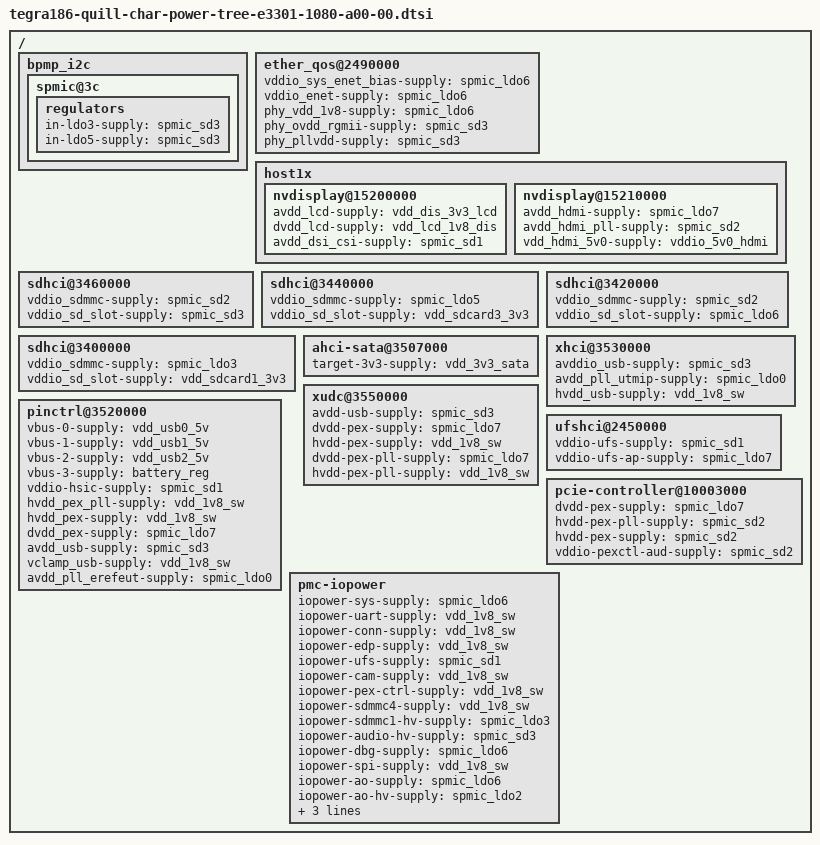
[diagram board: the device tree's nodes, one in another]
/*
 * Copyright (c) 2015, NVIDIA CORPORATION.  All rights reserved.
 *
 * This program is free software; you can redistribute it and/or modify
 * it under the terms of the GNU General Public License as published by
 * the Free Software Foundation; either version 2 of the License, or
 * (at your option) any later version.
 *
 * This program is distributed in the hope that it will be useful, but WITHOUT
 * ANY WARRANTY; without even the implied warranty of MERCHANTABILITY or
 * FITNESS FOR A PARTICULAR PURPOSE.  See the GNU General Public License for
 * more details.
 *
 */

#include "tegra186-quill-pb-spmic-e3301-1000-a00-00.dtsi"
#include "tegra186-quill-pb-fixed-e3301-1000-a00-00.dtsi"
#include "tegra186-cvb-slt-p2598-a00-e3340-1099-a00-00.dtsi"

/ {
	bpmp_i2c {
		spmic@3c {
			regulators {
				in-ldo3-supply = <&spmic_sd3>;
				in-ldo5-supply = <&spmic_sd3>;
			};
		};
	};

	ether_qos@2490000 {
		vddio_sys_enet_bias-supply = <&spmic_ldo6>;
		vddio_enet-supply = <&spmic_ldo6>;
		phy_vdd_1v8-supply = <&spmic_ldo6>;
		phy_ovdd_rgmii-supply = <&spmic_sd3>;
		phy_pllvdd-supply = <&spmic_sd3>;
	};

	host1x {
		nvdisplay@15200000 {
			avdd_lcd-supply = <&vdd_dis_3v3_lcd>;
			dvdd_lcd-supply = <&vdd_lcd_1v8_dis>;
			avdd_dsi_csi-supply = <&spmic_sd1>;
		};
		nvdisplay@15210000 {
			avdd_hdmi-supply = <&spmic_ldo7>;
			avdd_hdmi_pll-supply = <&spmic_sd2>;
			vdd_hdmi_5v0-supply = <&vddio_5v0_hdmi>;
		};
	};

	sdhci@3460000 {
		vddio_sdmmc-supply = <&spmic_sd2>;
		vddio_sd_slot-supply = <&spmic_sd3>;
	};

	sdhci@3440000 {
		vddio_sdmmc-supply = <&spmic_ldo5>;
		vddio_sd_slot-supply = <&vdd_sdcard3_3v3>;
	};

	sdhci@3420000 {
		vddio_sdmmc-supply = <&spmic_sd2>;
		vddio_sd_slot-supply = <&spmic_ldo6>;
	};

	sdhci@3400000 {
		vddio_sdmmc-supply = <&spmic_ldo3>;
		vddio_sd_slot-supply = <&vdd_sdcard1_3v3>;
	};

	ahci-sata@3507000 {
		target-3v3-supply = <&vdd_3v3_sata>;
	};

	xhci@3530000 {
		avddio_usb-supply = <&spmic_sd3>;
		avdd_pll_utmip-supply = <&spmic_ldo0>;
		hvdd_usb-supply =  <&vdd_1v8_sw>;
	};

	xudc@3550000 {
		avdd-usb-supply = <&spmic_sd3>;
		dvdd-pex-supply = <&spmic_ldo7>;
		hvdd-pex-supply =  <&vdd_1v8_sw>;
		dvdd-pex-pll-supply = <&spmic_ldo7>;
		hvdd-pex-pll-supply = <&vdd_1v8_sw>;
	};

	pinctrl@3520000 {
		vbus-0-supply = <&vdd_usb0_5v>;
		vbus-1-supply = <&vdd_usb1_5v>;
		vbus-2-supply = <&vdd_usb2_5v>;
		vbus-3-supply = <&battery_reg>;
		vddio-hsic-supply = <&spmic_sd1>;
		hvdd_pex_pll-supply = <&vdd_1v8_sw>;
		hvdd_pex-supply = <&vdd_1v8_sw>;
		dvdd_pex-supply = <&spmic_ldo7>;
		avdd_usb-supply = <&spmic_sd3>;
		vclamp_usb-supply = <&vdd_1v8_sw>;
		avdd_pll_erefeut-supply = <&spmic_ldo0>;
	};

	ufshci@2450000 {
		vddio-ufs-supply = <&spmic_sd1>;
		vddio-ufs-ap-supply = <&spmic_ldo7>;
	};

	pcie-controller@10003000 {
		dvdd-pex-supply = <&spmic_ldo7>;
		hvdd-pex-pll-supply = <&spmic_sd2>;
		hvdd-pex-supply = <&spmic_sd2>;
		vddio-pexctl-aud-supply = <&spmic_sd2>;
	};

	pmc-iopower {
		iopower-sys-supply = <&spmic_ldo6>;
		iopower-uart-supply = <&vdd_1v8_sw>;
		iopower-conn-supply = <&vdd_1v8_sw>;
		iopower-edp-supply = <&vdd_1v8_sw>;
		iopower-ufs-supply = <&spmic_sd1>;
		iopower-cam-supply = <&vdd_1v8_sw>;
		iopower-pex-ctrl-supply = <&vdd_1v8_sw>;
		iopower-sdmmc4-supply = <&vdd_1v8_sw>;
		iopower-sdmmc1-hv-supply = <&spmic_ldo3>;
		iopower-audio-hv-supply = <&spmic_sd3>;
		iopower-dbg-supply = <&spmic_ldo6>;
		iopower-spi-supply = <&vdd_1v8_sw>;
		iopower-ao-supply = <&spmic_ldo6>;
		iopower-ao-hv-supply = <&spmic_ldo2>;
		iopower-dmic-hv-supply =  <&spmic_sd3>;
		iopower-sdmmc2-hv-supply = <&spmic_sd3>;
		iopower-sdmmc3-hv-supply =  <&spmic_ldo5>;
	};
};
